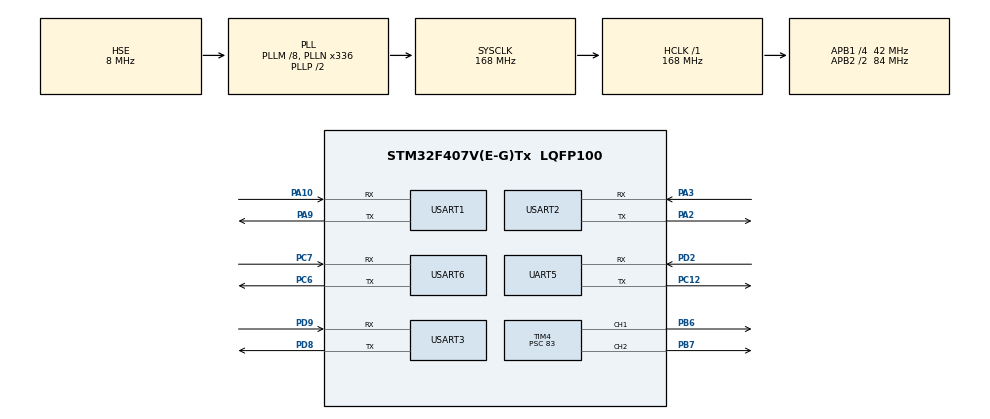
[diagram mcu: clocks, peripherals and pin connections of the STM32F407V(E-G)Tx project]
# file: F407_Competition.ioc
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Mcu.Family=STM32F4
Mcu.Name=STM32F407V(E-G)Tx
Mcu.Package=LQFP100
NVIC.PriorityGroup=NVIC_PRIORITYGROUP_4
PA10.Mode=Asynchronous
PA10.Signal=USART1_RX
PA13.Mode=Serial_Wire
PA13.Signal=SYS_JTMS-SWDIO
PA14.Mode=Serial_Wire
PA14.Signal=SYS_JTCK-SWCLK
PA2.Mode=Asynchronous
PA2.Signal=USART2_TX
PA3.Mode=Asynchronous
PA3.Signal=USART2_RX
PA9.Mode=Asynchronous
PA9.Signal=USART1_TX
PH0-OSC_IN.Mode=HSE-External-Oscillator
PH0-OSC_IN.Signal=RCC_OSC_IN
PH1-OSC_OUT.Mode=HSE-External-Oscillator
PH1-OSC_OUT.Signal=RCC_OSC_OUT
ProjectManager.HeapSize=0x200
ProjectManager.StackSize=0x800
ProjectManager.TargetToolchain=MDK-ARM V5.32
RCC.48MHZClocksFreq_Value=84000000
RCC.AHBFreq_Value=168000000
RCC.APB1CLKDivider=RCC_HCLK_DIV4
RCC.APB1Freq_Value=42000000
RCC.APB1TimFreq_Value=84000000
RCC.APB2CLKDivider=RCC_HCLK_DIV2
RCC.APB2Freq_Value=84000000
RCC.APB2TimFreq_Value=168000000
RCC.CortexFreq_Value=168000000
RCC.HCLKFreq_Value=168000000
RCC.HSE_VALUE=8000000
RCC.HSI_VALUE=16000000
RCC.LSE_VALUE=32768
RCC.PLLM=8
RCC.PLLN=336
RCC.PLLSourceVirtual=RCC_PLLSOURCE_HSE
RCC.SYSCLKFreq_VALUE=168000000
RCC.SYSCLKSource=RCC_SYSCLKSOURCE_PLLCLK
RCC.VCOOutputFreq_Value=336000000
USART1.VirtualMode=VM_ASYNC
USART2.VirtualMode=VM_ASYNC
board=custom
NVIC.USART6_IRQn=true\:5\:0\:false\:false\:true\:true\:true\:true
PC6.Mode=Asynchronous
PC6.Signal=USART6_TX
PC7.Mode=Asynchronous
PC7.Signal=USART6_RX
USART6.VirtualMode=VM_ASYNC
NVIC.USART1_IRQn=true\:5\:0\:false\:false\:true\:true\:true\:true
NVIC.USART2_IRQn=true\:5\:0\:false\:false\:true\:true\:true\:true
NVIC.UART5_IRQn=true\:5\:0\:false\:false\:true\:false\:true\:true
PC12.Mode=Asynchronous
PC12.Signal=UART5_TX
PD2.Mode=Asynchronous
PD2.Signal=UART5_RX
PD8.Mode=Asynchronous
PD8.Signal=USART3_TX
PD9.Mode=Asynchronous
PD9.Signal=USART3_RX
UART5.VirtualMode=Asynchronous
USART3.VirtualMode=VM_ASYNC
PB6.Signal=S_TIM4_CH1
PB6.GPIO_PuPd=GPIO_PULLDOWN
PB7.Signal=S_TIM4_CH2
PB7.GPIO_PuPd=GPIO_PULLDOWN
SH.S_TIM4_CH1.0=TIM4_CH1,PWM Generation1 CH1
SH.S_TIM4_CH2.0=TIM4_CH2,PWM Generation1 CH2
TIM4.AutoReloadPreload=TIM_AUTORELOAD_PRELOAD_ENABLE
TIM4.Channel-PWM\ Generation1\ CH1=TIM_CHANNEL_1
TIM4.Channel-PWM\ Generation1\ CH2=TIM_CHANNEL_2
TIM4.ClockDivision=TIM_CLOCKDIVISION_DIV1
TIM4.Period=19999
TIM4.Prescaler=83
TIM4.Pulse-PWM\ Generation1\ CH1=0
TIM4.Pulse-PWM\ Generation1\ CH2=0

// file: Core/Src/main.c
/* USER CODE BEGIN Header */
/*
 * F407 motor bench: USART1 console, USART2 motor bus, and TIM4 servo PWM.
 * This project never starts a motor automatically.
 */
/* USER CODE END Header */
#include "main.h"

/* USER CODE BEGIN Includes */
#include "competition.h"
#include "qr_bridge.h"
#include "servo.h"
/* USER CODE END Includes */

UART_HandleTypeDef huart1;
UART_HandleTypeDef huart2;
UART_HandleTypeDef huart6;
UART_HandleTypeDef huart3;
UART_HandleTypeDef huart5;
TIM_HandleTypeDef htim4;

void SystemClock_Config(void);
static void MX_GPIO_Init(void);
static void MX_USART1_UART_Init(void);
static void MX_USART2_UART_Init(void);
static void MX_USART6_UART_Init(void);
static void MX_USART3_UART_Init(void);
static void MX_UART5_Init(void);
static void MX_TIM4_Init(void);
void HAL_TIM_MspPostInit(TIM_HandleTypeDef *timer);

int main(void)
{

  /* MCU Configuration--------------------------------------------------------*/

  /* Reset of all peripherals, Initializes the Flash interface and the Systick. */
  HAL_Init();

  /* Configure the system clock */
  SystemClock_Config();

  /* Initialize all configured peripherals */
  MX_GPIO_Init();
  MX_USART1_UART_Init();
  MX_USART2_UART_Init();
  MX_USART6_UART_Init();
  MX_USART3_UART_Init();
  MX_UART5_Init();
  MX_TIM4_Init();
  /* USER CODE BEGIN 2 */
  Competition_Init(&huart1,&huart2,&huart6);
  QrBridge_Init(&huart5,&huart3);
  Servo_Init(&htim4);
  /* USER CODE END 2 */

  /* Infinite loop */
  while (1)
  {

    /* USER CODE BEGIN 3 */
    Competition_Poll();
  }
  /* USER CODE END 3 */
}

void SystemClock_Config(void)
{
  RCC_OscInitTypeDef RCC_OscInitStruct = {0};
  RCC_ClkInitTypeDef RCC_ClkInitStruct = {0};

  /** Configure the main internal regulator output voltage
  */
  __HAL_RCC_PWR_CLK_ENABLE();
  __HAL_PWR_VOLTAGESCALING_CONFIG(PWR_REGULATOR_VOLTAGE_SCALE1);

  /** Initializes the RCC Oscillators according to the specified parameters
  * in the RCC_OscInitTypeDef structure.
  */
  RCC_OscInitStruct.OscillatorType = RCC_OSCILLATORTYPE_HSE;
  RCC_OscInitStruct.HSEState = RCC_HSE_ON;
  RCC_OscInitStruct.PLL.PLLState = RCC_PLL_ON;
  RCC_OscInitStruct.PLL.PLLSource = RCC_PLLSOURCE_HSE;
  RCC_OscInitStruct.PLL.PLLM = 8;
  RCC_OscInitStruct.PLL.PLLN = 336;
  RCC_OscInitStruct.PLL.PLLP = RCC_PLLP_DIV2;
  RCC_OscInitStruct.PLL.PLLQ = 4;
  if (HAL_RCC_OscConfig(&RCC_OscInitStruct) != HAL_OK)
  {
    Error_Handler();
  }

  /** Initializes the CPU, AHB and APB buses clocks
  */
  RCC_ClkInitStruct.ClockType = RCC_CLOCKTYPE_HCLK|RCC_CLOCKTYPE_SYSCLK
                              |RCC_CLOCKTYPE_PCLK1|RCC_CLOCKTYPE_PCLK2;
  RCC_ClkInitStruct.SYSCLKSource = RCC_SYSCLKSOURCE_PLLCLK;
  RCC_ClkInitStruct.AHBCLKDivider = RCC_SYSCLK_DIV1;
  RCC_ClkInitStruct.APB1CLKDivider = RCC_HCLK_DIV4;
  RCC_ClkInitStruct.APB2CLKDivider = RCC_HCLK_DIV2;

  if (HAL_RCC_ClockConfig(&RCC_ClkInitStruct, FLASH_LATENCY_5) != HAL_OK)
  {
    Error_Handler();
  }
}

static void MX_USART1_UART_Init(void)
{

  huart1.Instance = USART1;
  huart1.Init.BaudRate = 115200;
  huart1.Init.WordLength = UART_WORDLENGTH_8B;
  huart1.Init.StopBits = UART_STOPBITS_1;
  huart1.Init.Parity = UART_PARITY_NONE;
  huart1.Init.Mode = UART_MODE_TX_RX;
  huart1.Init.HwFlowCtl = UART_HWCONTROL_NONE;
  huart1.Init.OverSampling = UART_OVERSAMPLING_16;
  if (HAL_UART_Init(&huart1) != HAL_OK)
  {
    Error_Handler();
  }

}

static void MX_USART2_UART_Init(void)
{

  huart2.Instance = USART2;
  huart2.Init.BaudRate = 115200;
  huart2.Init.WordLength = UART_WORDLENGTH_8B;
  huart2.Init.StopBits = UART_STOPBITS_1;
  huart2.Init.Parity = UART_PARITY_NONE;
  huart2.Init.Mode = UART_MODE_TX_RX;
  huart2.Init.HwFlowCtl = UART_HWCONTROL_NONE;
  huart2.Init.OverSampling = UART_OVERSAMPLING_16;
  if (HAL_UART_Init(&huart2) != HAL_OK)
  {
    Error_Handler();
  }

}

static void MX_GPIO_Init(void)
{

  /* GPIO Ports Clock Enable */
  __HAL_RCC_GPIOH_CLK_ENABLE();
  __HAL_RCC_GPIOA_CLK_ENABLE();

}

static void MX_USART6_UART_Init(void)
{

  huart6.Instance = USART6;
  huart6.Init.BaudRate = 115200;
  huart6.Init.WordLength = UART_WORDLENGTH_8B;
  huart6.Init.StopBits = UART_STOPBITS_1;
  huart6.Init.Parity = UART_PARITY_NONE;
  huart6.Init.Mode = UART_MODE_TX_RX;
  huart6.Init.HwFlowCtl = UART_HWCONTROL_NONE;
  huart6.Init.OverSampling = UART_OVERSAMPLING_16;
  if (HAL_UART_Init(&huart6) != HAL_OK)
  {
    Error_Handler();
  }

}

static void MX_USART3_UART_Init(void)
{

  huart3.Instance = USART3;
  huart3.Init.BaudRate = HMI_UART_BAUD;
  huart3.Init.WordLength = UART_WORDLENGTH_8B;
  huart3.Init.StopBits = UART_STOPBITS_1;
  huart3.Init.Parity = UART_PARITY_NONE;
  huart3.Init.Mode = UART_MODE_TX_RX;
  huart3.Init.HwFlowCtl = UART_HWCONTROL_NONE;
  huart3.Init.OverSampling = UART_OVERSAMPLING_16;
  if (HAL_UART_Init(&huart3) != HAL_OK)
  {
    Error_Handler();
  }

}

static void MX_UART5_Init(void)
{

  huart5.Instance = UART5;
  huart5.Init.BaudRate = QR_UART_BAUD;
  huart5.Init.WordLength = UART_WORDLENGTH_8B;
  huart5.Init.StopBits = UART_STOPBITS_1;
  huart5.Init.Parity = UART_PARITY_NONE;
  huart5.Init.Mode = UART_MODE_TX_RX;
  huart5.Init.HwFlowCtl = UART_HWCONTROL_NONE;
  huart5.Init.OverSampling = UART_OVERSAMPLING_16;
  if (HAL_UART_Init(&huart5) != HAL_OK)
  {
    Error_Handler();
  }

}

static void MX_TIM4_Init(void)
{
  TIM_OC_InitTypeDef config={0};
  htim4.Instance=TIM4;
  htim4.Init.Prescaler=83U;
  htim4.Init.CounterMode=TIM_COUNTERMODE_UP;
  htim4.Init.Period=19999U;
  htim4.Init.ClockDivision=TIM_CLOCKDIVISION_DIV1;
  htim4.Init.AutoReloadPreload=TIM_AUTORELOAD_PRELOAD_ENABLE;
  if (HAL_TIM_PWM_Init(&htim4)!=HAL_OK) Error_Handler();
  config.OCMode=TIM_OCMODE_PWM1;
  config.Pulse=0U;
  config.OCPolarity=TIM_OCPOLARITY_HIGH;
  config.OCFastMode=TIM_OCFAST_DISABLE;
  if (HAL_TIM_PWM_ConfigChannel(&htim4,&config,TIM_CHANNEL_1)!=HAL_OK ||
      HAL_TIM_PWM_ConfigChannel(&htim4,&config,TIM_CHANNEL_2)!=HAL_OK) Error_Handler();
  HAL_TIM_MspPostInit(&htim4);
}

void Error_Handler(void)
{
  __disable_irq();
  while (1)
  {
  }
}
